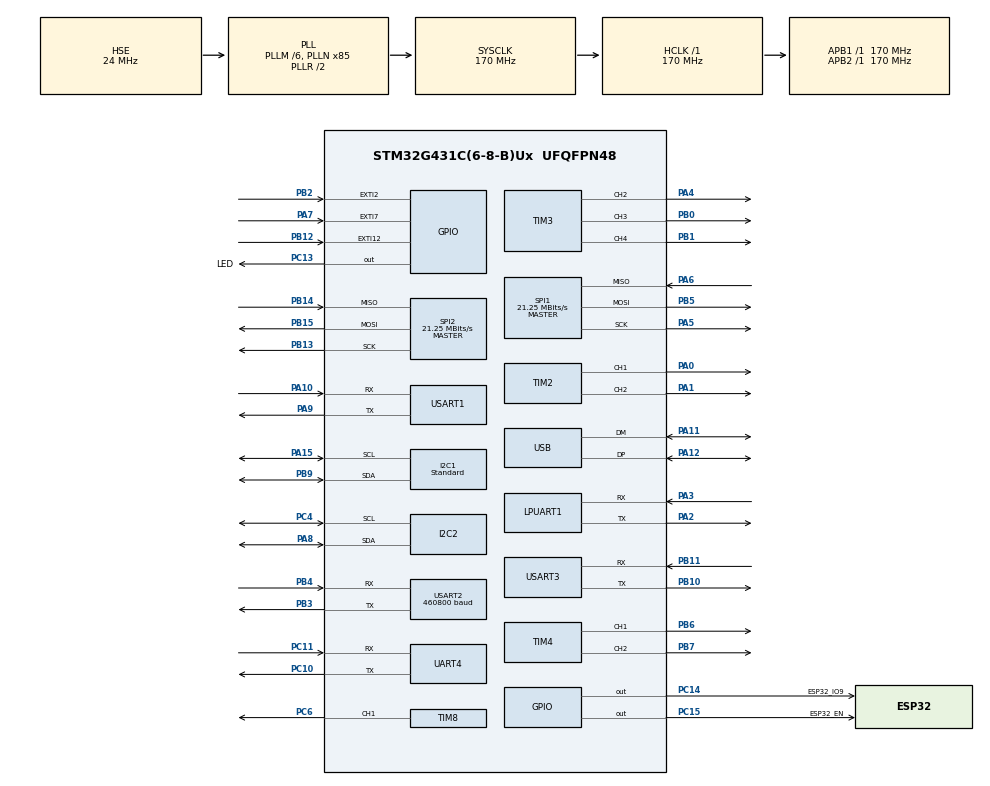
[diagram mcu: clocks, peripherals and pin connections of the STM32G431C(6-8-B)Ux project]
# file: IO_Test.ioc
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I2C1.I2C_Speed_Mode=I2C_Standard
I2C1.Timing=0x40B285C2
I2C2.Timing=0x40B285C2
Mcu.Family=STM32G4
Mcu.Name=STM32G431C(6-8-B)Ux
Mcu.Package=UFQFPN48
NVIC.PriorityGroup=NVIC_PRIORITYGROUP_4
NVIC.TIM1_UP_TIM16_IRQn=true\:0\:0\:false\:false\:true\:true\:true\:true
NVIC.UART4_IRQn=true\:0\:0\:false\:false\:true\:true\:true\:true
NVIC.USART2_IRQn=true\:0\:0\:false\:false\:true\:true\:true\:true
NVIC.USART3_IRQn=true\:0\:0\:false\:false\:true\:true\:true\:true
NVIC.USB_LP_IRQn=true\:0\:0\:false\:false\:true\:false\:true\:true
PA0.Signal=S_TIM2_CH1
PA1.Signal=S_TIM2_CH2
PA10.Mode=Asynchronous
PA10.Signal=USART1_RX
PA11.Mode=Device
PA11.Signal=USB_DM
PA12.Mode=Device
PA12.Signal=USB_DP
PA13.Mode=Serial_Wire
PA13.Signal=SYS_JTMS-SWDIO
PA14.Mode=Serial_Wire
PA14.Signal=SYS_JTCK-SWCLK
PA15.Mode=I2C
PA15.Signal=I2C1_SCL
PA2.Mode=Asynchronous
PA2.Signal=LPUART1_TX
PA3.Mode=Asynchronous
PA3.Signal=LPUART1_RX
PA4.Signal=S_TIM3_CH2
PA5.Mode=Full_Duplex_Master
PA5.Signal=SPI1_SCK
PA6.Mode=Full_Duplex_Master
PA6.Signal=SPI1_MISO
PA7.Signal=GPXTI7
PA8.Mode=I2C
PA8.Signal=I2C2_SDA
PA9.Mode=Asynchronous
PA9.Signal=USART1_TX
PB0.Signal=S_TIM3_CH3
PB1.Signal=S_TIM3_CH4
PB10.Mode=Asynchronous
PB10.Signal=USART3_TX
PB11.Mode=Asynchronous
PB11.Signal=USART3_RX
PB12.Signal=GPXTI12
PB13.Mode=Full_Duplex_Master
PB13.Signal=SPI2_SCK
PB14.Mode=Full_Duplex_Master
PB14.Signal=SPI2_MISO
PB15.Mode=Full_Duplex_Master
PB15.Signal=SPI2_MOSI
PB2.Signal=GPXTI2
PB3.Mode=Asynchronous
PB3.Signal=USART2_TX
PB4.Mode=Asynchronous
PB4.Signal=USART2_RX
PB5.Mode=Full_Duplex_Master
PB5.Signal=SPI1_MOSI
PB6.Signal=S_TIM4_CH1
PB7.Signal=S_TIM4_CH2
PB9.Mode=I2C
PB9.Signal=I2C1_SDA
PC10.Mode=Asynchronous
PC10.Signal=UART4_TX
PC11.Mode=Asynchronous
PC11.Signal=UART4_RX
PC13.GPIO_Label=LED
PC13.Signal=GPIO_Output
PC14-OSC32_IN.GPIO_Label=ESP32_IO9
PC14-OSC32_IN.Signal=GPIO_Output
PC15-OSC32_OUT.GPIO_Label=ESP32_EN
PC15-OSC32_OUT.Signal=GPIO_Output
PC4.Mode=I2C
PC4.Signal=I2C2_SCL
PC6.Signal=S_TIM8_CH1
PF0-OSC_IN.Mode=HSE-External-Oscillator
PF0-OSC_IN.Signal=RCC_OSC_IN
PF1-OSC_OUT.Mode=HSE-External-Oscillator
PF1-OSC_OUT.Signal=RCC_OSC_OUT
ProjectManager.HeapSize=0x200
ProjectManager.StackSize=0x400
ProjectManager.TargetToolchain=MDK-ARM V5.32
RCC.ADC12Freq_Value=170000000
RCC.AHBFreq_Value=170000000
RCC.APB1Freq_Value=170000000
RCC.APB1TimFreq_Value=170000000
RCC.APB2Freq_Value=170000000
RCC.APB2TimFreq_Value=170000000
RCC.CK48CLockSelection=RCC_USBCLKSOURCE_HSI48
RCC.CortexFreq_Value=170000000
RCC.EXTERNAL_CLOCK_VALUE=12288000
RCC.HCLKFreq_Value=170000000
RCC.HSE_VALUE=24000000
RCC.HSI48_VALUE=48000000
RCC.HSI_VALUE=16000000
RCC.LSE_VALUE=32768
RCC.PLLM=RCC_PLLM_DIV6
RCC.PLLN=85
RCC.PLLSourceVirtual=RCC_PLLSOURCE_HSE
RCC.SYSCLKFreq_VALUE=170000000
RCC.SYSCLKSource=RCC_SYSCLKSOURCE_PLLCLK
RCC.USBFreq_Value=48000000
RCC.VCOOutputFreq_Value=340000000
SH.S_TIM2_CH1.0=TIM2_CH1,PWM Generation1 CH1
SH.S_TIM2_CH2.0=TIM2_CH2,PWM Generation2 CH2
SH.S_TIM3_CH2.0=TIM3_CH2,PWM Generation2 CH2
SH.S_TIM3_CH3.0=TIM3_CH3,PWM Generation3 CH3
SH.S_TIM3_CH4.0=TIM3_CH4,PWM Generation4 CH4
SH.S_TIM4_CH1.0=TIM4_CH1,PWM Generation1 CH1
SH.S_TIM4_CH2.0=TIM4_CH2,PWM Generation2 CH2
SH.S_TIM8_CH1.0=TIM8_CH1,PWM Generation1 CH1
SPI1.BaudRatePrescaler=SPI_BAUDRATEPRESCALER_8
SPI1.CalculateBaudRate=21.25 MBits/s
SPI1.Direction=SPI_DIRECTION_2LINES
SPI1.Mode=SPI_MODE_MASTER
SPI1.VirtualType=VM_MASTER
SPI2.BaudRatePrescaler=SPI_BAUDRATEPRESCALER_8
SPI2.CalculateBaudRate=21.25 MBits/s
SPI2.Direction=SPI_DIRECTION_2LINES
SPI2.Mode=SPI_MODE_MASTER
SPI2.VirtualType=VM_MASTER
TIM1.PeriodNoDither=19999
TIM1.Prescaler=16999
TIM2.Channel-PWM\ Generation1\ CH1=TIM_CHANNEL_1
TIM2.Channel-PWM\ Generation2\ CH2=TIM_CHANNEL_2
TIM3.Channel-PWM\ Generation2\ CH2=TIM_CHANNEL_2
TIM3.Channel-PWM\ Generation3\ CH3=TIM_CHANNEL_3
TIM3.Channel-PWM\ Generation4\ CH4=TIM_CHANNEL_4
TIM4.Channel-PWM\ Generation1\ CH1=TIM_CHANNEL_1
TIM4.Channel-PWM\ Generation2\ CH2=TIM_CHANNEL_2
TIM8.Channel-PWM\ Generation1\ CH1=TIM_CHANNEL_1
USART1.VirtualMode-Asynchronous=VM_ASYNC
USART2.BaudRate=460800
USART2.VirtualMode-Asynchronous=VM_ASYNC
USART3.VirtualMode-Asynchronous=VM_ASYNC
USB_DEVICE.CLASS_NAME_FS=CDC
USB_DEVICE.VirtualMode=Cdc
USB_DEVICE.VirtualModeFS=Cdc_FS
VP_SYS_VS_DBSignals.Mode=DisableDeadBatterySignals
VP_TIM1_VS_ClockSourceINT.Mode=Internal
VP_USB_DEVICE_VS_USB_DEVICE_CDC_FS.Mode=CDC_FS
board=custom

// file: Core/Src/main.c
/* USER CODE BEGIN Header */
/**
  ******************************************************************************
  * @file           : main.c
  * @brief          : Main program body
  ******************************************************************************
  * @attention
  *
  * Copyright (c) 2025 STMicroelectronics.
  * All rights reserved.
  *
  * This software is licensed under terms that can be found in the LICENSE file
  * in the root directory of this software component.
  * If no LICENSE file comes with this software, it is provided AS-IS.
  *
  ******************************************************************************
  */
/* USER CODE END Header */
#include "main.h"
#include "i2c.h"
#include "usart.h"
#include "spi.h"
#include "tim.h"
#include "usb_device.h"
#include "gpio.h"

/* USER CODE BEGIN Includes */
#include "POM_ESP32_C3.h"
/* USER CODE END Includes */

void SystemClock_Config(void);

int main(void)
{

  /* MCU Configuration--------------------------------------------------------*/

  /* Reset of all peripherals, Initializes the Flash interface and the Systick. */
  HAL_Init();

  /* Configure the system clock */
  SystemClock_Config();

  /* Initialize all configured peripherals */
  MX_GPIO_Init();
  MX_USB_Device_Init();
  MX_USART2_UART_Init();
  MX_USART3_UART_Init();
  MX_UART4_Init();
  MX_I2C1_Init();
  MX_LPUART1_UART_Init();
  MX_USART1_UART_Init();
  MX_I2C2_Init();
  MX_SPI1_Init();
  MX_SPI2_Init();
  MX_TIM2_Init();
  MX_TIM3_Init();
  MX_TIM4_Init();
  MX_TIM8_Init();
  MX_TIM1_Init();
  /* USER CODE BEGIN 2 */
  Disable_ESP32_C3();
  HAL_TIM_Base_Start_IT(&htim1);
  /* USER CODE END 2 */

  /* Infinite loop */
  while (1)
  {

  }
}

void SystemClock_Config(void)
{
  RCC_OscInitTypeDef RCC_OscInitStruct = {0};
  RCC_ClkInitTypeDef RCC_ClkInitStruct = {0};

  /** Configure the main internal regulator output voltage
  */
  HAL_PWREx_ControlVoltageScaling(PWR_REGULATOR_VOLTAGE_SCALE1_BOOST);

  /** Initializes the RCC Oscillators according to the specified parameters
  * in the RCC_OscInitTypeDef structure.
  */
  RCC_OscInitStruct.OscillatorType = RCC_OSCILLATORTYPE_HSI48|RCC_OSCILLATORTYPE_HSE;
  RCC_OscInitStruct.HSEState = RCC_HSE_ON;
  RCC_OscInitStruct.HSI48State = RCC_HSI48_ON;
  RCC_OscInitStruct.PLL.PLLState = RCC_PLL_ON;
  RCC_OscInitStruct.PLL.PLLSource = RCC_PLLSOURCE_HSE;
  RCC_OscInitStruct.PLL.PLLM = RCC_PLLM_DIV6;
  RCC_OscInitStruct.PLL.PLLN = 85;
  RCC_OscInitStruct.PLL.PLLP = RCC_PLLP_DIV2;
  RCC_OscInitStruct.PLL.PLLQ = RCC_PLLQ_DIV2;
  RCC_OscInitStruct.PLL.PLLR = RCC_PLLR_DIV2;
  if (HAL_RCC_OscConfig(&RCC_OscInitStruct) != HAL_OK)
  {
    Error_Handler();
  }

  /** Initializes the CPU, AHB and APB buses clocks
  */
  RCC_ClkInitStruct.ClockType = RCC_CLOCKTYPE_HCLK|RCC_CLOCKTYPE_SYSCLK
                              |RCC_CLOCKTYPE_PCLK1|RCC_CLOCKTYPE_PCLK2;
  RCC_ClkInitStruct.SYSCLKSource = RCC_SYSCLKSOURCE_PLLCLK;
  RCC_ClkInitStruct.AHBCLKDivider = RCC_SYSCLK_DIV1;
  RCC_ClkInitStruct.APB1CLKDivider = RCC_HCLK_DIV1;
  RCC_ClkInitStruct.APB2CLKDivider = RCC_HCLK_DIV1;

  if (HAL_RCC_ClockConfig(&RCC_ClkInitStruct, FLASH_LATENCY_4) != HAL_OK)
  {
    Error_Handler();
  }
}

/* USER CODE BEGIN 4 */
void HAL_TIM_PeriodElapsedCallback(TIM_HandleTypeDef *htim)
{
  if(htim->Instance == htim1.Instance)
  {
    HAL_GPIO_TogglePin(LED_GPIO_Port,LED_Pin);
  }
}
/* USER CODE END 4 */

void Error_Handler(void)
{
  __disable_irq();
  while (1)
  {
  }
}
